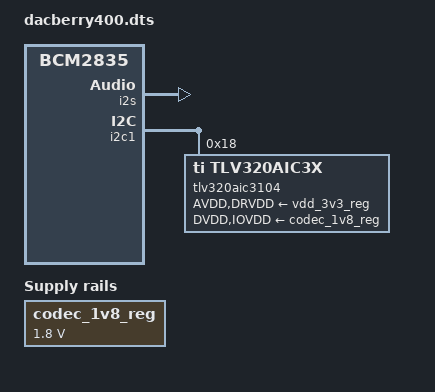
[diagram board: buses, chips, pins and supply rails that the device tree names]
// Definitions for TLV DACberry400
/dts-v1/;
/plugin/;
/ {
	compatible = "brcm,bcm2835";

	fragment@0 {
		target = <&i2s>;
		__overlay__ {
			status = "okay";
		};
	};

	fragment@1 {
                target-path = "/";
                __overlay__ {
                        codec_1v8_reg: codec-1v8-reg {
                                compatible = "regulator-fixed";
                                regulator-name = "tlv320aic3104_1v8";
                                regulator-min-microvolt = <1800000>;
                                regulator-max-microvolt = <1800000>;
                                regulator-always-on;
                        };
                };
        };


	fragment@2 {
		target = <&i2c1>;
		__overlay__ {
			#address-cells = <1>;
                        #size-cells = <0>;
			status = "okay";

			tlv320aic3104@18 {
				#sound-dai-cells = <0>;
				reg = <0x18>;
				compatible = "ti,tlv320aic3x";
				status = "okay";
				AVDD-supply = <&vdd_3v3_reg>;
				DRVDD-supply = <&vdd_3v3_reg>;
				DVDD-supply = <&codec_1v8_reg>;
				IOVDD-supply = <&codec_1v8_reg>;
			};
		};
	};

	fragment@3 {
		target = <&sound>;
		__overlay__ {
			compatible = "osaelectronics, dacberry400";
			i2s-controller = <&i2s>;
			status = "okay";
		};
	};

	__overrides__ {
        
	};
};
